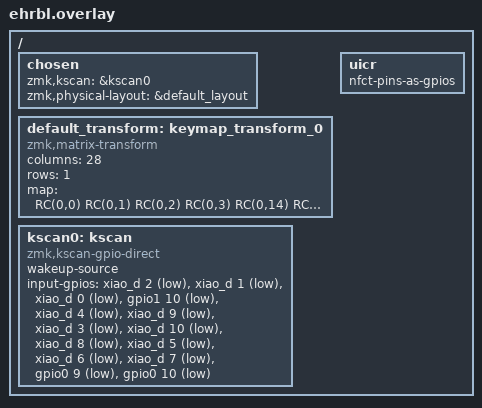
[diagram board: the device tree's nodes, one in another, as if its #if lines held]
/*
* Copyright (c) 2022 The ZMK Contributors
*
* SPDX-License-Identifier: MIT
*/

#include <dt-bindings/zmk/matrix_transform.h>
#include "ehrbl-layouts.dtsi"

/ {
	chosen {
		zmk,kscan = &kscan0;
		zmk,physical-layout = &default_layout;
	};
	
	default_transform: keymap_transform_0 {
		compatible = "zmk,matrix-transform";
        #ifdef DIRECT
            columns = <28>;
            rows = <1>;

            map = <
            RC(0,0) RC(0,1)  RC(0,2)  RC(0,3) RC(0,14) RC(0,15) RC(0,16) RC(0,17) 
            RC(0,4) RC(0,5)  RC(0,6)  RC(0,7) RC(0,18) RC(0,19) RC(0,20) RC(0,21) 
            RC(0,8) RC(0,9) RC(0,10) RC(0,11) RC(0,22) RC(0,23) RC(0,24) RC(0,25)
                            RC(0,12) RC(0,13) RC(0,26) RC(0,27)
            >;
        #else
            columns = <8>;
            rows = <4>;
		
            map = <
            RC(0,0) RC(0,1) RC(0,2)  RC(0,3)  RC(0,4) RC(0,5) RC(0,6) RC(0,7) 
            RC(1,0) RC(1,1) RC(1,2)  RC(1,3)  RC(1,4) RC(1,5) RC(1,6) RC(1,7)
            RC(2,0) RC(2,1) RC(2,2)  RC(2,3)  RC(2,4) RC(2,5) RC(2,6) RC(2,7)
                            RC(3,2)  RC(3,3)  RC(3,4) RC(3,5)
            >;
        #endif
	};
	// RESET: GPIO 0.18
	// NFC: GPIO 0.9 and 0.10
	// PDM: GPIO 0.16, 1.0, and 1.10 (top to bottom on right side of PDM pad)
	// https://www.reddit.com/r/olkb/comments/11hl7is/extra_gpio_on_seeed_xiao_controllers_via_zmk/

	#ifdef DIRECT
	uicr {
		nfct-pins-as-gpios;
	};
	#endif
	
	kscan0: kscan {
        #ifdef DIRECT
            compatible = "zmk,kscan-gpio-direct";
            wakeup-source;
            input-gpios
            = <&xiao_d  2 (GPIO_ACTIVE_LOW | GPIO_PULL_UP)>
            , <&xiao_d  1 (GPIO_ACTIVE_LOW | GPIO_PULL_UP)>
            , <&xiao_d  0 (GPIO_ACTIVE_LOW | GPIO_PULL_UP)>
            , <&gpio1  10 (GPIO_ACTIVE_LOW | GPIO_PULL_UP)>
            , <&xiao_d  4 (GPIO_ACTIVE_LOW | GPIO_PULL_UP)>
            , <&xiao_d  9 (GPIO_ACTIVE_LOW | GPIO_PULL_UP)>
            , <&xiao_d  3 (GPIO_ACTIVE_LOW | GPIO_PULL_UP)>
            , <&xiao_d 10 (GPIO_ACTIVE_LOW | GPIO_PULL_UP)>
            , <&xiao_d  8 (GPIO_ACTIVE_LOW | GPIO_PULL_UP)>
            , <&xiao_d  5 (GPIO_ACTIVE_LOW | GPIO_PULL_UP)>
            , <&xiao_d  6 (GPIO_ACTIVE_LOW | GPIO_PULL_UP)>
            , <&xiao_d  7 (GPIO_ACTIVE_LOW | GPIO_PULL_UP)>
            , <&gpio0   9 (GPIO_ACTIVE_LOW | GPIO_PULL_UP)>
            , <&gpio0  10 (GPIO_ACTIVE_LOW | GPIO_PULL_UP)>
            ;
        #else
            compatible = "zmk,kscan-gpio-matrix";
            wakeup-source;
            diode-direction = "col2row";
            col-gpios
                = <&xiao_d 3 GPIO_ACTIVE_HIGH>
                , <&xiao_d 2 GPIO_ACTIVE_HIGH>
                , <&xiao_d 1 GPIO_ACTIVE_HIGH>
                , <&xiao_d 0 GPIO_ACTIVE_HIGH>
                ;
            row-gpios
                = <&xiao_d 10 (GPIO_ACTIVE_HIGH | GPIO_PULL_DOWN)>
                , <&xiao_d 9 (GPIO_ACTIVE_HIGH | GPIO_PULL_DOWN)>
                , <&xiao_d 8 (GPIO_ACTIVE_HIGH | GPIO_PULL_DOWN)>
                , <&xiao_d 7 (GPIO_ACTIVE_HIGH | GPIO_PULL_DOWN)>
                ;
        #endif
    };
};
